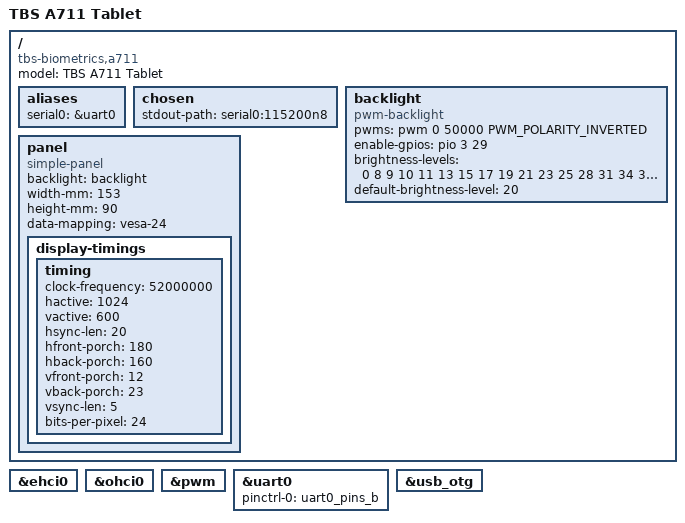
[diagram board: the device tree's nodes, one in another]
/*
 * Copyright 2017 Ondřej Jirman
 * Ondřej Jirman <megous@megous.com>
 *
 * This file is dual-licensed: you can use it either under the terms
 * of the GPL or the X11 license, at your option. Note that this dual
 * licensing only applies to this file, and not this project as a
 * whole.
 *
 *  a) This file is free software; you can redistribute it and/or
 *     modify it under the terms of the GNU General Public License as
 *     published by the Free Software Foundation; either version 2 of the
 *     License, or (at your option) any later version.
 *
 *     This file is distributed in the hope that it will be useful,
 *     but WITHOUT ANY WARRANTY; without even the implied warranty of
 *     MERCHANTABILITY or FITNESS FOR A PARTICULAR PURPOSE.  See the
 *     GNU General Public License for more details.
 *
 * Or, alternatively,
 *
 *  b) Permission is hereby granted, free of charge, to any person
 *     obtaining a copy of this software and associated documentation
 *     files (the "Software"), to deal in the Software without
 *     restriction, including without limitation the rights to use,
 *     copy, modify, merge, publish, distribute, sublicense, and/or
 *     sell copies of the Software, and to permit persons to whom the
 *     Software is furnished to do so, subject to the following
 *     conditions:
 *
 *     The above copyright notice and this permission notice shall be
 *     included in all copies or substantial portions of the Software.
 *
 *     THE SOFTWARE IS PROVIDED "AS IS", WITHOUT WARRANTY OF ANY KIND,
 *     EXPRESS OR IMPLIED, INCLUDING BUT NOT LIMITED TO THE WARRANTIES
 *     OF MERCHANTABILITY, FITNESS FOR A PARTICULAR PURPOSE AND
 *     NONINFRINGEMENT. IN NO EVENT SHALL THE AUTHORS OR COPYRIGHT
 *     HOLDERS BE LIABLE FOR ANY CLAIM, DAMAGES OR OTHER LIABILITY,
 *     WHETHER IN AN ACTION OF CONTRACT, TORT OR OTHERWISE, ARISING
 *     FROM, OUT OF OR IN CONNECTION WITH THE SOFTWARE OR THE USE OR
 *     OTHER DEALINGS IN THE SOFTWARE.
 */

/dts-v1/;
#include "sun8i-a83t.dtsi"

#include <dt-bindings/gpio/gpio.h>
#include <dt-bindings/pwm/pwm.h>

/ {
	model = "TBS A711 Tablet";
	compatible = "tbs-biometrics,a711", "allwinner,sun8i-a83t";

	aliases {
		serial0 = &uart0;
	};

	chosen {
		stdout-path = "serial0:115200n8";
	};

	backlight: backlight {
		compatible = "pwm-backlight";
		pwms = <&pwm 0 50000 PWM_POLARITY_INVERTED>;
		enable-gpios = <&pio 3 29 GPIO_ACTIVE_HIGH>;

		brightness-levels = <0 8 9 10 11 13 15 17 19 21 23 25 28
				     31 34 37 40 44 48 52 56 61 67 72 78
				     84 91 98 106 115 124 133 143 154
				     166 179 192 207 223 239 255>;
		default-brightness-level = <20>;
	};

	panel {
		compatible = "simple-panel";
		backlight = <&backlight>;

		width-mm = <153>;
		height-mm = <90>;
		data-mapping = "vesa-24";

		display-timings {
			timing {
				/* 1024x600 @60Hz */
				clock-frequency = <52000000>;
				hactive = <1024>;
				vactive = <600>;
				hsync-len = <20>;
				hfront-porch = <180>;
				hback-porch = <160>;
				vfront-porch = <12>;
				vback-porch = <23>;
				vsync-len = <5>;
				bits-per-pixel = <24>;
			};
		};
	};
};

&ehci0 {
	status = "okay";
};

&ohci0 {
	status = "okay";
};

&pwm {
	status = "okay";
};

&uart0 {
	pinctrl-names = "default";
	pinctrl-0 = <&uart0_pins_b>;
	status = "okay";
};

&usb_otg {
	status = "okay";
};
